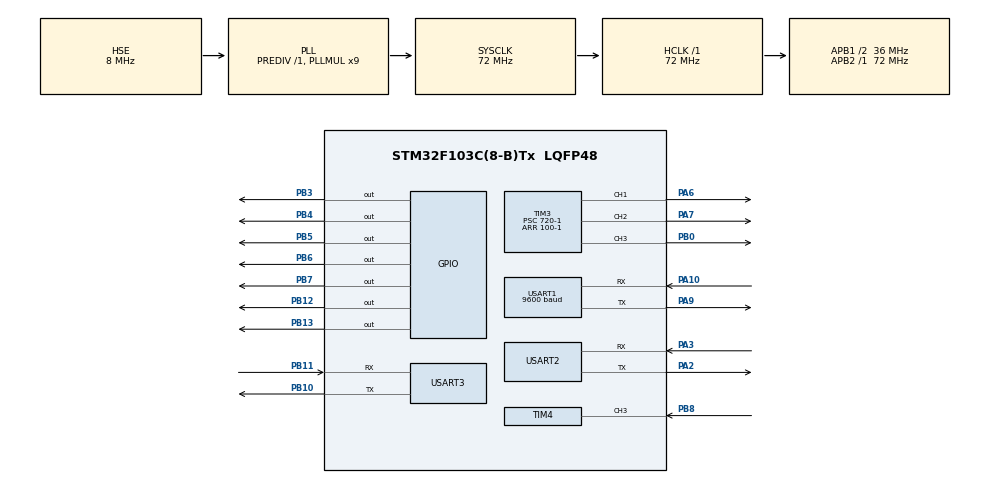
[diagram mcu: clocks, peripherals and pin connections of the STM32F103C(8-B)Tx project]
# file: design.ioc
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Mcu.Family=STM32F1
Mcu.Name=STM32F103C(8-B)Tx
Mcu.Package=LQFP48
NVIC.PriorityGroup=NVIC_PRIORITYGROUP_4
NVIC.TIM2_IRQn=true\:0\:0\:false\:false\:true\:true\:true
NVIC.TIM4_IRQn=true\:0\:0\:false\:false\:true\:true\:true
NVIC.USART1_IRQn=true\:0\:0\:false\:false\:true\:true\:true
PA10.Mode=Asynchronous
PA10.Signal=USART1_RX
PA13.Mode=Serial_Wire
PA13.Signal=SYS_JTMS-SWDIO
PA14.Mode=Serial_Wire
PA14.Signal=SYS_JTCK-SWCLK
PA2.Mode=Asynchronous
PA2.Signal=USART2_TX
PA3.Mode=Asynchronous
PA3.Signal=USART2_RX
PA6.Signal=S_TIM3_CH1
PA7.Signal=S_TIM3_CH2
PA9.Mode=Asynchronous
PA9.Signal=USART1_TX
PB0.Signal=S_TIM3_CH3
PB10.Mode=Asynchronous
PB10.Signal=USART3_TX
PB11.Mode=Asynchronous
PB11.Signal=USART3_RX
PB12.Signal=GPIO_Output
PB13.Signal=GPIO_Output
PB3.GPIO_Speed=GPIO_SPEED_FREQ_HIGH
PB3.PinState=GPIO_PIN_RESET
PB3.Signal=GPIO_Output
PB4.GPIO_Speed=GPIO_SPEED_FREQ_HIGH
PB4.PinState=GPIO_PIN_RESET
PB4.Signal=GPIO_Output
PB5.GPIO_Speed=GPIO_SPEED_FREQ_HIGH
PB5.PinState=GPIO_PIN_RESET
PB5.Signal=GPIO_Output
PB6.GPIO_Speed=GPIO_SPEED_FREQ_HIGH
PB6.PinState=GPIO_PIN_RESET
PB6.Signal=GPIO_Output
PB7.Signal=GPIO_Output
PB8.Signal=S_TIM4_CH3
PD0-OSC_IN.Mode=HSE-External-Oscillator
PD0-OSC_IN.Signal=RCC_OSC_IN
PD1-OSC_OUT.Mode=HSE-External-Oscillator
PD1-OSC_OUT.Signal=RCC_OSC_OUT
ProjectManager.HeapSize=0x200
ProjectManager.StackSize=0x400
ProjectManager.TargetToolchain=MDK-ARM V5.27
RCC.AHBFreq_Value=72000000
RCC.APB1CLKDivider=RCC_HCLK_DIV2
RCC.APB1Freq_Value=36000000
RCC.APB1TimFreq_Value=72000000
RCC.APB2Freq_Value=72000000
RCC.APB2TimFreq_Value=72000000
RCC.HCLKFreq_Value=72000000
RCC.PLLMUL=RCC_PLL_MUL9
RCC.PLLSourceVirtual=RCC_PLLSOURCE_HSE
RCC.SYSCLKFreq_VALUE=72000000
RCC.SYSCLKSource=RCC_SYSCLKSOURCE_PLLCLK
RCC.USBFreq_Value=72000000
SH.S_TIM3_CH1.0=TIM3_CH1,PWM Generation1 CH1
SH.S_TIM3_CH2.0=TIM3_CH2,PWM Generation2 CH2
SH.S_TIM3_CH3.0=TIM3_CH3,PWM Generation3 CH3
SH.S_TIM4_CH3.0=TIM4_CH3,Input_Capture3_from_TI3
TIM2.AutoReloadPreload=TIM_AUTORELOAD_PRELOAD_ENABLE
TIM2.Period=10-1
TIM2.Prescaler=72-1
TIM3.AutoReloadPreload=TIM_AUTORELOAD_PRELOAD_ENABLE
TIM3.Channel-PWM\ Generation1\ CH1=TIM_CHANNEL_1
TIM3.Channel-PWM\ Generation2\ CH2=TIM_CHANNEL_2
TIM3.Channel-PWM\ Generation3\ CH3=TIM_CHANNEL_3
TIM3.Period=100-1
TIM3.Prescaler=720-1
TIM4.AutoReloadPreload=TIM_AUTORELOAD_PRELOAD_ENABLE
TIM4.Channel-Input_Capture3_from_TI3=TIM_CHANNEL_3
TIM4.Prescaler=72-1
USART1.BaudRate=9600
USART1.VirtualMode=VM_ASYNC
USART2.VirtualMode=VM_ASYNC
USART3.VirtualMode=VM_ASYNC
VP_TIM2_VS_ClockSourceINT.Mode=Internal
VP_TIM3_VS_ClockSourceINT.Mode=Internal
VP_TIM4_VS_ClockSourceINT.Mode=Internal
board=custom

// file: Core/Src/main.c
#include "main.h"
#include "tim.h"
#include "usart.h"
#include "gpio.h"
#include "motor.h"
#include "app_rtos.h"
#include <stdio.h>

void SystemClock_Config(void);

int main(void)
{
  /* MCU Configuration--------------------------------------------------------*/

  /* Reset of all peripherals, Initializes the Flash interface and the Systick. */
  HAL_Init();

  /* Configure the system clock */
  SystemClock_Config();

  /* Initialize all configured peripherals */
  MX_GPIO_Init();
  MX_TIM2_Init();  /* 保留配置备用；RTOS 版本改用 TIM4 捕获时间戳测距，不再启动 TIM2 中断 */
  MX_TIM3_Init();
  MX_TIM4_Init();
  MX_USART1_UART_Init();
  MX_USART2_UART_Init();
  MX_USART3_UART_Init();

  /* USER CODE BEGIN 2 */
  HAL_UART_Transmit(&huart2, (uint8_t *)"OK", sizeof("OK") - 1, 100); /* 沿用原工程：开机提示发往 USART2 */
  printf("\r\n");

  /* 电机 PWM：CH1 左轮、CH2 右轮、CH3 吸尘器（CH4 扫把预留，与原工程一致） */
  HAL_TIM_PWM_Start(&htim3, TIM_CHANNEL_1);
  HAL_TIM_PWM_Start(&htim3, TIM_CHANNEL_2);
  HAL_TIM_PWM_Start(&htim3, TIM_CHANNEL_3);
  // HAL_TIM_PWM_Start(&htim3, TIM_CHANNEL_4); // 扫把部分

  Motor_SetSpeed(0, 0); /* 上电先让两个轮子停下来（同时把方向引脚设为正转） */
  Motor_SetSpeed(1, 0);
  besom_stop();

  /* 超声波回波输入捕获：TIM4_CH3，计数频率 1MHz（1us 分辨率） */
  HAL_TIM_IC_Start_IT(&htim4, TIM_CHANNEL_3);

  /* 创建 RTOS 对象与 4 个任务，然后启动调度器 */
  App_RtosInit();
  vTaskStartScheduler();
  /* USER CODE END 2 */

  /* 正常情况下调度器不会返回；走到这里说明内核堆内存不足，启动失败 */
  Error_Handler();
  while (1)
  {
  }
}

void SystemClock_Config(void)
{
  RCC_OscInitTypeDef RCC_OscInitStruct = {0};
  RCC_ClkInitTypeDef RCC_ClkInitStruct = {0};

  /** Initializes the RCC Oscillators according to the specified parameters
   * in the RCC_OscInitTypeDef structure.
   */
  RCC_OscInitStruct.OscillatorType = RCC_OSCILLATORTYPE_HSE;
  RCC_OscInitStruct.HSEState = RCC_HSE_ON;
  RCC_OscInitStruct.HSEPredivValue = RCC_HSE_PREDIV_DIV1;
  RCC_OscInitStruct.HSIState = RCC_HSI_ON;
  RCC_OscInitStruct.PLL.PLLState = RCC_PLL_ON;
  RCC_OscInitStruct.PLL.PLLSource = RCC_PLLSOURCE_HSE;
  RCC_OscInitStruct.PLL.PLLMUL = RCC_PLL_MUL9;
  if (HAL_RCC_OscConfig(&RCC_OscInitStruct) != HAL_OK)
  {
    Error_Handler();
  }
  /** Initializes the CPU, AHB and APB buses clocks
   */
  RCC_ClkInitStruct.ClockType = RCC_CLOCKTYPE_HCLK | RCC_CLOCKTYPE_SYSCLK | RCC_CLOCKTYPE_PCLK1 | RCC_CLOCKTYPE_PCLK2;
  RCC_ClkInitStruct.SYSCLKSource = RCC_SYSCLKSOURCE_PLLCLK;
  RCC_ClkInitStruct.AHBCLKDivider = RCC_SYSCLK_DIV1;
  RCC_ClkInitStruct.APB1CLKDivider = RCC_HCLK_DIV2;
  RCC_ClkInitStruct.APB2CLKDivider = RCC_HCLK_DIV1;

  if (HAL_RCC_ClockConfig(&RCC_ClkInitStruct, FLASH_LATENCY_2) != HAL_OK)
  {
    Error_Handler();
  }
}

void Error_Handler(void)
{
  __disable_irq();
  while (1)
  {
  }
}

/************************ (C) COPYRIGHT STMicroelectronics *****END OF FILE****/
